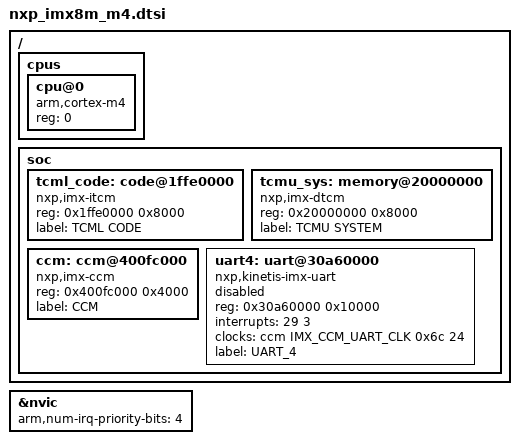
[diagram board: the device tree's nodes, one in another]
/*
 * Copyright (c) 2017, NXP
 *
 * SPDX-License-Identifier: Apache-2.0
 */

#include <arm/armv7-m.dtsi>
#include <dt-bindings/clock/imx_ccm.h>
#include <dt-bindings/rdc/imx_rdc.h>

/ {
	cpus {
		#address-cells = <1>;
		#size-cells = <0>;

		cpu@0 {
			device_type = "cpu";
			compatible = "arm,cortex-m4";
			reg = <0>;
		};
	};

	soc {
		tcml_code: code@1ffe0000 {
			compatible = "nxp,imx-itcm";
			reg = <0x1ffe0000 0x8000>;
			label = "TCML CODE";
		};

		tcmu_sys: memory@20000000 {
			compatible = "nxp,imx-dtcm";
			reg = <0x20000000 0x8000>;
			label = "TCMU SYSTEM";
		};

		ccm: ccm@400fc000 {
			compatible = "nxp,imx-ccm";
			reg = <0x400fc000 0x4000>;
			label = "CCM";

			#clock-cells = <3>;
		};

		/* For now only uart2 is supported and
		 * tested with the serial driver
		 */
		uart4: uart@30a60000 {
			compatible = "nxp,kinetis-imx-uart";
			reg = <0x30a60000 0x10000>;
			interrupts = <29 3>;
			clocks = <&ccm IMX_CCM_UART_CLK 0x6c 24>;
			label = "UART_4";
			status = "disabled";
		};
	};
};

&nvic {
	arm,num-irq-priority-bits = <4>;
};
